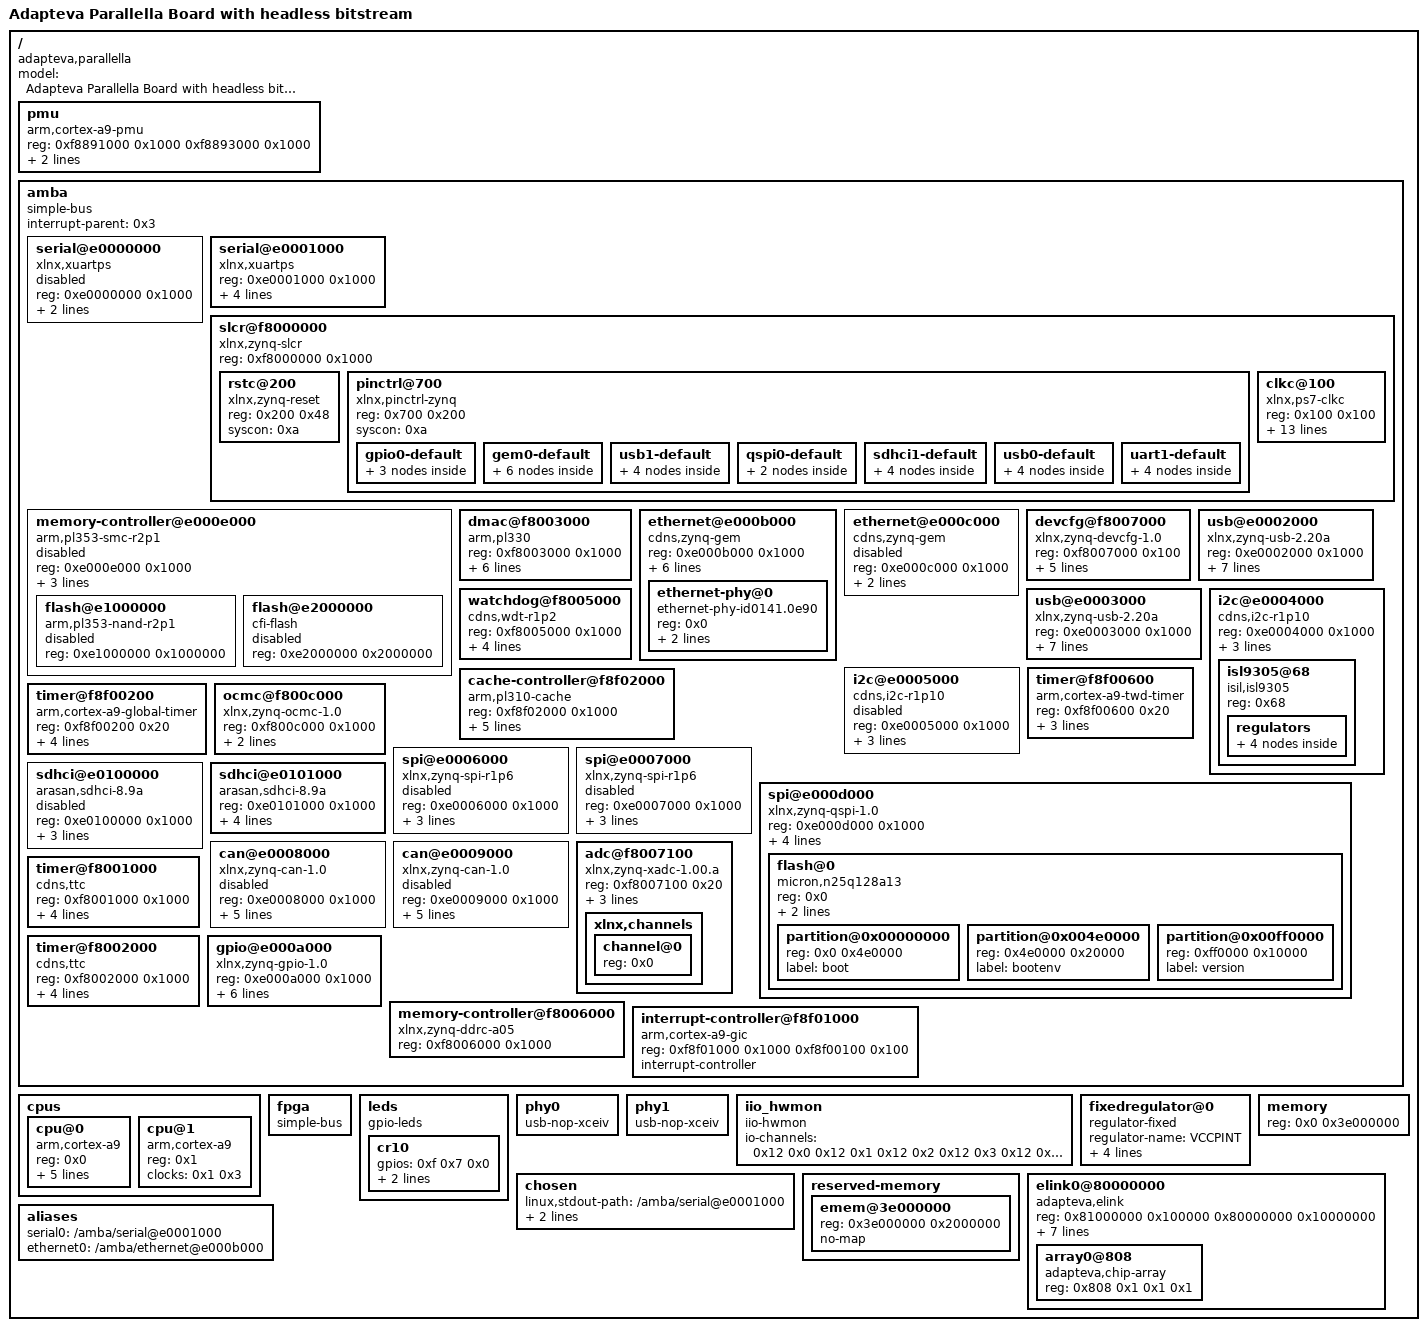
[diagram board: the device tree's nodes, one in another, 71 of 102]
/include/ "custom.dtsi";
/dts-v1/;
/ {
	model = "Adapteva Parallella Board with headless bitstream";
	compatible = "adapteva,parallella", "xlnx,zynq-7000";
	#address-cells = <0x1>;
	#size-cells = <0x1>;

	pmu {
		reg = <0xf8891000 0x1000 0xf8893000 0x1000>;
		interrupts = <0x0 0x5 0x4 0x0 0x6 0x4>;
		compatible = "arm,cortex-a9-pmu";
		interrupt-parent = <0x3>;
	};

	amba {
		compatible = "simple-bus";
		ranges;
		#address-cells = <0x1>;
		#size-cells = <0x1>;
		interrupt-parent = <0x3>;

		serial@e0000000 {
			reg = <0xe0000000 0x1000>;
			interrupts = <0x0 0x1b 0x4>;
			compatible = "xlnx,xuartps", "cdns,uart-r1p8";
			clock-names = "uart_clk", "pclk";
			clocks = <0x1 0x17 0x1 0x28>;
			status = "disabled";
		};

		serial@e0001000 {
			reg = <0xe0001000 0x1000>;
			interrupts = <0x0 0x32 0x4>;
			pinctrl-0 = <0x5>;
			compatible = "xlnx,xuartps", "cdns,uart-r1p8";
			clock-names = "uart_clk", "pclk";
			clocks = <0x1 0x18 0x1 0x29>;
			status = "okay";
			cdns,rx-no-pullup;
			pinctrl-names = "default";
		};

		slcr@f8000000 {
			reg = <0xf8000000 0x1000>;
			compatible = "xlnx,zynq-slcr", "syscon", "simple-mfd";
			ranges;
			#address-cells = <0x1>;
			phandle = <0xa>;
			#size-cells = <0x1>;
			linux,phandle = <0xa>;

			rstc@200 {
				reg = <0x200 0x48>;
				#reset-cells = <0x1>;
				compatible = "xlnx,zynq-reset";
				syscon = <0xa>;
			};

			pinctrl@700 {
				reg = <0x700 0x200>;
				compatible = "xlnx,pinctrl-zynq";
				syscon = <0xa>;

				gpio0-default {
					phandle = <0x4>;
					linux,phandle = <0x4>;

					mux {
						function = "gpio0";
						groups = "gpio0_7_grp";
					};

					conf {
						io-standard = <0x3>;
						slew-rate = <0x0>;
						groups = "gpio0_7_grp";
					};

					conf-pull-up {
						pins = "MIO7";
						bias-pull-up;
					};
				};

				gem0-default {
					phandle = <0x8>;
					linux,phandle = <0x8>;

					mux {
						function = "ethernet0";
						groups = "ethernet0_0_grp";
					};

					conf {
						io-standard = <0x1>;
						slew-rate = <0x0>;
						groups = "ethernet0_0_grp";
					};

					conf-rx {
						pins = "MIO22", "MIO23", "MIO24", "MIO25", "MIO26", "MIO27";
						bias-high-impedance;
						low-power-disable;
					};

					conf-tx {
						pins = "MIO16", "MIO17", "MIO18", "MIO19", "MIO20", "MIO21";
						bias-disable;
						low-power-enable;
					};

					conf-mdio {
						io-standard = <0x1>;
						bias-disable;
						slew-rate = <0x0>;
						groups = "mdio0_0_grp";
					};

					mux-mdio {
						function = "mdio0";
						groups = "mdio0_0_grp";
					};
				};

				usb1-default {
					phandle = <0xe>;
					linux,phandle = <0xe>;

					mux {
						function = "usb1";
						groups = "usb1_0_grp";
					};

					conf {
						io-standard = <0x1>;
						slew-rate = <0x0>;
						groups = "usb1_0_grp";
					};

					conf-rx {
						pins = "MIO41", "MIO43", "MIO48";
						bias-high-impedance;
					};

					conf-tx {
						pins = "MIO40", "MIO42", "MIO44", "MIO45", "MIO46", "MIO47", "MIO49", "MIO50", "MIO51";
						bias-disable;
					};
				};

				qspi0-default {
					phandle = <0x6>;
					linux,phandle = <0x6>;

					mux {
						function = "qspi0";
						groups = "qspi0_0_grp";
					};

					conf {
						io-standard = <0x3>;
						groups = "qspi0_0_grp";
					};
				};

				sdhci1-default {
					phandle = <0x9>;
					linux,phandle = <0x9>;

					mux {
						function = "sdio1";
						groups = "sdio1_0_grp";
					};

					conf {
						io-standard = <0x1>;
						bias-disable;
						slew-rate = <0x0>;
						groups = "sdio1_0_grp";
					};

					conf-cd {
						bias-pull-up;
						io-standard = <0x3>;
						slew-rate = <0x0>;
						groups = "gpio0_0_grp";
						bias-high-impedance;
					};

					mux-cd {
						function = "sdio1_cd";
						groups = "gpio0_0_grp";
					};
				};

				usb0-default {
					phandle = <0xc>;
					linux,phandle = <0xc>;

					mux {
						function = "usb0";
						groups = "usb0_0_grp";
					};

					conf {
						io-standard = <0x1>;
						slew-rate = <0x0>;
						groups = "usb0_0_grp";
					};

					conf-rx {
						pins = "MIO29", "MIO31", "MIO36";
						bias-high-impedance;
					};

					conf-tx {
						pins = "MIO28", "MIO30", "MIO32", "MIO33", "MIO34", "MIO35", "MIO37", "MIO38", "MIO39";
						bias-disable;
					};
				};

				uart1-default {
					phandle = <0x5>;
					linux,phandle = <0x5>;

					mux {
						function = "uart1";
						groups = "uart1_0_grp";
					};

					conf {
						io-standard = <0x3>;
						slew-rate = <0x0>;
						groups = "uart1_0_grp";
					};

					conf-rx {
						pins = "MIO9";
						bias-high-impedance;
					};

					conf-tx {
						pins = "MIO8";
						bias-disable = <0x0>;
					};
				};
			};

			clkc@100 {
				reg = <0x100 0x100>;
				#clock-cells = <0x1>;
				compatible = "xlnx,ps7-clkc";
				clock-output-names = "armpll", "ddrpll", "iopll", "cpu_6or4x", "cpu_3or2x", "cpu_2x", "cpu_1x", "ddr2x", "ddr3x", "dci", "lqspi", "smc", "pcap", "gem0", "gem1", "fclk0", "fclk1", "fclk2", "fclk3", "can0", "can1", "sdio0", "sdio1", "uart0", "uart1", "spi0", "spi1", "dma", "usb0_aper", "usb1_aper", "gem0_aper", "gem1_aper", "sdio0_aper", "sdio1_aper", "spi0_aper", "spi1_aper", "can0_aper", "can1_aper", "i2c0_aper", "i2c1_aper", "uart0_aper", "uart1_aper", "gpio_aper", "lqspi_aper", "smc_aper", "swdt", "dbg_trc", "dbg_apb";
				ps-clk-frequency = <0x1fca055>;
				phandle = <0x1>;
				fclk-enable = <0xf>;
				linux,phandle = <0x1>;
			};
		};

		memory-controller@e000e000 {
			reg = <0xe000e000 0x1000>;
			interrupts = <0x0 0x12 0x4>;
			compatible = "arm,pl353-smc-r2p1";
			clock-names = "memclk", "aclk";
			clocks = <0x1 0xb 0x1 0x2c>;
			ranges;
			status = "disabled";
			#address-cells = <0x1>;
			#size-cells = <0x1>;
			interrupt-parent = <0x3>;

			flash@e1000000 {
				reg = <0xe1000000 0x1000000>;
				compatible = "arm,pl353-nand-r2p1";
				status = "disabled";
				#address-cells = <0x1>;
				#size-cells = <0x1>;
			};

			flash@e2000000 {
				reg = <0xe2000000 0x2000000>;
				compatible = "cfi-flash";
				status = "disabled";
				#address-cells = <0x1>;
				#size-cells = <0x1>;
			};
		};

		dmac@f8003000 {
			reg = <0xf8003000 0x1000>;
			interrupts = <0x0 0xd 0x4 0x0 0xe 0x4 0x0 0xf 0x4 0x0 0x10 0x4 0x0 0x11 0x4 0x0 0x28 0x4 0x0 0x29 0x4 0x0 0x2a 0x4 0x0 0x2b 0x4>;
			compatible = "arm,pl330", "arm,primecell";
			clock-names = "apb_pclk";
			interrupt-names = "abort", "dma0", "dma1", "dma2", "dma3", "dma4", "dma5", "dma6", "dma7";
			clocks = <0x1 0x1b>;
			#dma-requests = <0x4>;
			#dma-channels = <0x8>;
			#dma-cells = <0x1>;
			interrupt-parent = <0x3>;
		};

		ethernet@e000b000 {
			reg = <0xe000b000 0x1000>;
			interrupts = <0x0 0x16 0x4>;
			phy-handle = <0x7>;
			pinctrl-0 = <0x8>;
			compatible = "cdns,zynq-gem", "cdns,gem";
			local-mac-address = [04 4f 8b 00 35 5e];
			clock-names = "pclk", "hclk", "tx_clk";
			phy-mode = "rgmii-id";
			clocks = <0x1 0x1e 0x1 0x1e 0x1 0xd>;
			status = "okay";
			#address-cells = <0x1>;
			#size-cells = <0x0>;
			pinctrl-names = "default";

			ethernet-phy@0 {
				reg = <0x0>;
				compatible = "ethernet-phy-id0141.0e90", "ethernet-phy-ieee802.3-c22";
				marvell,reg-init = <0x3 0x10 0xff00 0x1e 0x3 0x11 0xfff0 0xa>;
				phandle = <0x7>;
				linux,phandle = <0x7>;
			};
		};

		ethernet@e000c000 {
			reg = <0xe000c000 0x1000>;
			interrupts = <0x0 0x2d 0x4>;
			compatible = "cdns,zynq-gem", "cdns,gem";
			clock-names = "pclk", "hclk", "tx_clk";
			clocks = <0x1 0x1f 0x1 0x1f 0x1 0xe>;
			status = "disabled";
			#address-cells = <0x1>;
			#size-cells = <0x0>;
		};

		devcfg@f8007000 {
			reg = <0xf8007000 0x100>;
			interrupts = <0x0 0x8 0x4>;
			compatible = "xlnx,zynq-devcfg-1.0";
			clock-names = "ref_clk", "fclk0", "fclk1", "fclk2", "fclk3";
			clocks = <0x1 0xc 0x1 0xf 0x1 0x10 0x1 0x11 0x1 0x12>;
			syscon = <0xa>;
			interrupt-parent = <0x3>;
		};

		usb@e0002000 {
			reg = <0xe0002000 0x1000>;
			interrupts = <0x0 0x15 0x4>;
			pinctrl-0 = <0xc>;
			compatible = "xlnx,zynq-usb-2.20a", "chipidea,usb2";
			dr_mode = "host";
			clocks = <0x1 0x1c>;
			phy_type = "ulpi";
			status = "okay";
			usb-phy = <0xb>;
			pinctrl-names = "default";
			interrupt-parent = <0x3>;
		};

		usb@e0003000 {
			reg = <0xe0003000 0x1000>;
			interrupts = <0x0 0x2c 0x4>;
			pinctrl-0 = <0xe>;
			compatible = "xlnx,zynq-usb-2.20a", "chipidea,usb2";
			dr_mode = "peripheral";
			clocks = <0x1 0x1d>;
			phy_type = "ulpi";
			status = "okay";
			usb-phy = <0xd>;
			pinctrl-names = "default";
			interrupt-parent = <0x3>;
		};

		i2c@e0004000 {
			reg = <0xe0004000 0x1000>;
			interrupts = <0x0 0x19 0x4>;
			compatible = "cdns,i2c-r1p10";
			clocks = <0x1 0x26>;
			status = "okay";
			#address-cells = <0x1>;
			#size-cells = <0x0>;
			interrupt-parent = <0x3>;

			isl9305@68 {
				reg = <0x68>;
				compatible = "isil,isl9305", "isl,isl9305";

				regulators {

					dcd1 {
						regulator-name = "VDD_DSP";
						regulator-min-microvolt = <0xdbba0>;
						regulator-max-microvolt = <0x124f80>;
						phandle = <0x11>;
						linux,phandle = <0x11>;
					};

					dcd2 {
						regulator-name = "1P35V";
						regulator-always-on;
					};

					ldo1 {
						regulator-name = "VDD_ADJ";
						regulator-always-on;
					};

					ldo2 {
						regulator-name = "VDD_GPIO";
						regulator-always-on;
					};
				};
			};
		};

		i2c@e0005000 {
			reg = <0xe0005000 0x1000>;
			interrupts = <0x0 0x30 0x4>;
			compatible = "cdns,i2c-r1p10";
			clocks = <0x1 0x27>;
			status = "disabled";
			#address-cells = <0x1>;
			#size-cells = <0x0>;
			interrupt-parent = <0x3>;
		};

		watchdog@f8005000 {
			reg = <0xf8005000 0x1000>;
			interrupts = <0x0 0x9 0x1>;
			compatible = "cdns,wdt-r1p2";
			timeout-sec = <0xa>;
			clocks = <0x1 0x2d>;
			interrupt-parent = <0x3>;
		};

		cache-controller@f8f02000 {
			reg = <0xf8f02000 0x1000>;
			interrupts = <0x0 0x2 0x4>;
			arm,tag-latency = <0x2 0x2 0x2>;
			compatible = "arm,pl310-cache";
			arm,data-latency = <0x3 0x2 0x2>;
			cache-level = <0x2>;
			cache-unified;
		};

		timer@f8f00200 {
			reg = <0xf8f00200 0x20>;
			interrupts = <0x1 0xb 0x301>;
			compatible = "arm,cortex-a9-global-timer";
			clocks = <0x1 0x4>;
			tied-to-cpu-freq;
			interrupt-parent = <0x3>;
		};

		timer@f8f00600 {
			reg = <0xf8f00600 0x20>;
			interrupts = <0x1 0xd 0x301>;
			compatible = "arm,cortex-a9-twd-timer";
			clocks = <0x1 0x4>;
			interrupt-parent = <0x3>;
		};

		ocmc@f800c000 {
			reg = <0xf800c000 0x1000>;
			interrupts = <0x0 0x3 0x4>;
			compatible = "xlnx,zynq-ocmc-1.0";
			interrupt-parent = <0x3>;
		};

		spi@e0006000 {
			reg = <0xe0006000 0x1000>;
			interrupts = <0x0 0x1a 0x4>;
			compatible = "xlnx,zynq-spi-r1p6";
			clock-names = "ref_clk", "pclk";
			clocks = <0x1 0x19 0x1 0x22>;
			status = "disabled";
			#address-cells = <0x1>;
			#size-cells = <0x0>;
			interrupt-parent = <0x3>;
		};

		spi@e0007000 {
			reg = <0xe0007000 0x1000>;
			interrupts = <0x0 0x31 0x4>;
			compatible = "xlnx,zynq-spi-r1p6";
			clock-names = "ref_clk", "pclk";
			clocks = <0x1 0x1a 0x1 0x23>;
			status = "disabled";
			#address-cells = <0x1>;
			#size-cells = <0x0>;
			interrupt-parent = <0x3>;
		};

		spi@e000d000 {
			reg = <0xe000d000 0x1000>;
			interrupts = <0x0 0x13 0x4>;
			pinctrl-0 = <0x6>;
			compatible = "xlnx,zynq-qspi-1.0";
			clock-names = "ref_clk", "pclk";
			clocks = <0x1 0xa 0x1 0x2b>;
			status = "okay";
			#address-cells = <0x1>;
			#size-cells = <0x0>;
			pinctrl-names = "default";
			interrupt-parent = <0x3>;

			flash@0 {
				reg = <0x0>;
				compatible = "micron,n25q128a13";
				m25p,fast-read;
				spi-max-frequency = <0x2faf080>;
				#address-cells = <0x1>;
				#size-cells = <0x1>;

				partition@0x00000000 {
					reg = <0x0 0x4e0000>;
					label = "boot";
				};

				partition@0x004e0000 {
					reg = <0x4e0000 0x20000>;
					label = "bootenv";
				};

				partition@0x00ff0000 {
					reg = <0xff0000 0x10000>;
					label = "version";
				};
			};
		};

		sdhci@e0100000 {
			reg = <0xe0100000 0x1000>;
			interrupts = <0x0 0x18 0x4>;
			compatible = "arasan,sdhci-8.9a";
			clock-names = "clk_xin", "clk_ahb";
			clocks = <0x1 0x15 0x1 0x20>;
			status = "disabled";
			interrupt-parent = <0x3>;
		};

		sdhci@e0101000 {
			reg = <0xe0101000 0x1000>;
			interrupts = <0x0 0x2f 0x4>;
			pinctrl-0 = <0x9>;
			compatible = "arasan,sdhci-8.9a";
			clock-names = "clk_xin", "clk_ahb";
			clocks = <0x1 0x16 0x1 0x21>;
			status = "okay";
			pinctrl-names = "default";
			interrupt-parent = <0x3>;
		};

		can@e0008000 {
			reg = <0xe0008000 0x1000>;
			interrupts = <0x0 0x1c 0x4>;
			compatible = "xlnx,zynq-can-1.0";
			clock-names = "can_clk", "pclk";
			tx-fifo-depth = <0x40>;
			clocks = <0x1 0x13 0x1 0x24>;
			status = "disabled";
			rx-fifo-depth = <0x40>;
			interrupt-parent = <0x3>;
		};

		can@e0009000 {
			reg = <0xe0009000 0x1000>;
			interrupts = <0x0 0x33 0x4>;
			compatible = "xlnx,zynq-can-1.0";
			clock-names = "can_clk", "pclk";
			tx-fifo-depth = <0x40>;
			clocks = <0x1 0x14 0x1 0x25>;
			status = "disabled";
			rx-fifo-depth = <0x40>;
			interrupt-parent = <0x3>;
		};

		adc@f8007100 {
			reg = <0xf8007100 0x20>;
			interrupts = <0x0 0x7 0x4>;
			compatible = "xlnx,zynq-xadc-1.00.a";
			clocks = <0x1 0xc>;
			phandle = <0x12>;
			#io-channel-cells = <0x1>;
			linux,phandle = <0x12>;
			interrupt-parent = <0x3>;

			xlnx,channels {
				#address-cells = <0x1>;
				#size-cells = <0x0>;

				channel@0 {
					reg = <0x0>;
					#io-channel-cells = <0x0>;
				};
			};
		};

		timer@f8001000 {
			reg = <0xf8001000 0x1000>;
			interrupts = <0x0 0xa 0x4 0x0 0xb 0x4 0x0 0xc 0x4>;
			compatible = "cdns,ttc";
			clocks = <0x1 0x6>;
			interrupt-parent = <0x3>;
		};

		timer@f8002000 {
			reg = <0xf8002000 0x1000>;
			interrupts = <0x0 0x25 0x4 0x0 0x26 0x4 0x0 0x27 0x4>;
			compatible = "cdns,ttc";
			clocks = <0x1 0x6>;
			interrupt-parent = <0x3>;
		};

		gpio@e000a000 {
			reg = <0xe000a000 0x1000>;
			interrupts = <0x0 0x14 0x4>;
			pinctrl-0 = <0x4>;
			#gpio-cells = <0x2>;
			compatible = "xlnx,zynq-gpio-1.0";
			clocks = <0x1 0x2a>;
			#interrupt-cells = <0x2>;
			phandle = <0xf>;
			interrupt-controller;
			gpio-controller;
			pinctrl-names = "default";
			linux,phandle = <0xf>;
			interrupt-parent = <0x3>;
		};

		memory-controller@f8006000 {
			reg = <0xf8006000 0x1000>;
			compatible = "xlnx,zynq-ddrc-a05";
		};

		interrupt-controller@f8f01000 {
			reg = <0xf8f01000 0x1000 0xf8f00100 0x100>;
			compatible = "arm,cortex-a9-gic";
			#interrupt-cells = <0x3>;
			phandle = <0x3>;
			interrupt-controller;
			linux,phandle = <0x3>;
		};
	};

	cpus {
		#address-cells = <0x1>;
		#size-cells = <0x0>;

		cpu@0 {
			reg = <0x0>;
			compatible = "arm,cortex-a9";
			device_type = "cpu";
			clocks = <0x1 0x3>;
			clock-latency = <0x3e8>;
			operating-points = <0xa2c2b 0xf4240 0x51616 0xf4240>;
			cpu0-supply = <0x2>;
		};

		cpu@1 {
			reg = <0x1>;
			compatible = "arm,cortex-a9";
			device_type = "cpu";
			clocks = <0x1 0x3>;
		};
	};

	fpga {
		compatible = "simple-bus";
		ranges;
		#address-cells = <0x1>;
		#size-cells = <0x1>;
	};

	leds {
		compatible = "gpio-leds";

		cr10 {
			gpios = <0xf 0x7 0x0>;
			label = "parallella:cr10:usr";
			default-state = "on";
		};
	};

	phy0 {
		compatible = "usb-nop-xceiv";
		#phy-cells = <0x0>;
		status = "okay";
		phandle = <0xb>;
		linux,phandle = <0xb>;
	};

	phy1 {
		compatible = "usb-nop-xceiv";
		#phy-cells = <0x0>;
		status = "okay";
		phandle = <0xd>;
		linux,phandle = <0xd>;
	};

	iio_hwmon {
		compatible = "iio-hwmon";
		io-channels = <0x12 0x0 0x12 0x1 0x12 0x2 0x12 0x3 0x12 0x4 0x12 0x5 0x12 0x6 0x12 0x7 0x12 0x8>;
	};

	fixedregulator@0 {
		regulator-name = "VCCPINT";
		compatible = "regulator-fixed";
		regulator-always-on;
		regulator-min-microvolt = <0xf4240>;
		regulator-max-microvolt = <0xf4240>;
		phandle = <0x2>;
		regulator-boot-on;
		linux,phandle = <0x2>;
	};

	chosen {
		linux,stdout-path = "/amba/serial@e0001000";
		bootargs = "console=ttyPS0,115200 earlyprintk root=/dev/mmcblk0p2 rootfstype=ext4 rw rootwait";
	};

	memory {
		reg = <0x0 0x3e000000>;
		device_type = "memory";
	};

	reserved-memory {
		ranges;
		#address-cells = <0x1>;
		#size-cells = <0x1>;

		emem@3e000000 {
			reg = <0x3e000000 0x2000000>;
			no-map;
			phandle = <0x10>;
			linux,phandle = <0x10>;
		};
	};

	elink0@80000000 {
		reg = <0x81000000 0x100000 0x80000000 0x10000000>;
		interrupts = <0x0 0x37 0x1>;
		compatible = "adapteva,elink";
		clock-names = "fclk0", "fclk1", "fclk2", "fclk3";
		clocks = <0x1 0xf 0x1 0x10 0x1 0x11 0x1 0x12>;
		#address-cells = <0x2>;
		vdd-supply = <0x11>;
		adapteva,mmu = <0x8e000000 0x3e000000 0x2000000>;
		memory-region = <0x10>;
		#size-cells = <0x2>;
		adapteva,no-coreid-pinout;
		interrupt-parent = <0x3>;

		array0@808 {
			reg = <0x808 0x1 0x1 0x1>;
			compatible = "adapteva,chip-array";
		};
	};

	aliases {
		serial0 = "/amba/serial@e0001000";
		ethernet0 = "/amba/ethernet@e000b000";
	};
};
